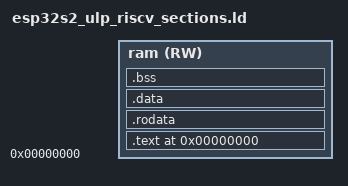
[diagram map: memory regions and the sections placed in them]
/****************************************************************************
 * boards/xtensa/esp32s2/common/scripts/esp32s2_ulp_riscv_sections.ld
 *
 * SPDX-License-Identifier: Apache-2.0
 *
 * Licensed to the Apache Software Foundation (ASF) under one or more
 * contributor license agreements.  See the NOTICE file distributed with
 * this work for additional information regarding copyright ownership.  The
 * ASF licenses this file to you under the Apache License, Version 2.0 (the
 * "License"); you may not use this file except in compliance with the
 * License.  You may obtain a copy of the License at
 *
 *   http://www.apache.org/licenses/LICENSE-2.0
 *
 * Unless required by applicable law or agreed to in writing, software
 * distributed under the License is distributed on an "AS IS" BASIS, WITHOUT
 * WARRANTIES OR CONDITIONS OF ANY KIND, either express or implied.  See the
 * License for the specific language governing permissions and limitations
 * under the License.
 *
 ****************************************************************************/

#include <nuttx/config.h>

ENTRY(reset_vector)

MEMORY
{
    ram(RW) : ORIGIN = 0, LENGTH = CONFIG_ESP32S2_ULP_COPROC_RESERVE_MEM
}

SECTIONS
{
    . = ORIGIN(ram);
    .text :
    {
        *ulp_riscv_vectors.S.obj(.text.vectors) /* Default reset vector must link to offset 0x0 */
        *(.text)
        *(.text*)
    } >ram

    .rodata ALIGN(4):
    {
        *(.rodata)
        *(.rodata*)
    } > ram

    .data ALIGN(4):
    {
        *(.data)
        *(.data*)
        *(.sdata)
        *(.sdata*)
    } > ram

    .bss ALIGN(4) :
    {
        *(.bss)
        *(.bss*)
        *(.sbss)
        *(.sbss*)
    } >ram

    __stack_top = ORIGIN(ram) + LENGTH(ram);
}
